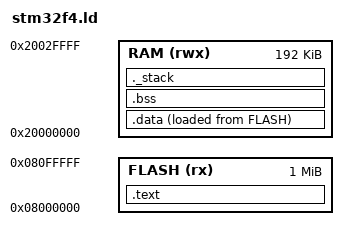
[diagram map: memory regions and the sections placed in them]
ENTRY(Reset_Handler)

MEMORY
{
    FLASH (rx)  : ORIGIN = 0x08000000, LENGTH = 1024K
    RAM   (rwx) : ORIGIN = 0x20000000, LENGTH = 192K
}

SECTIONS
{
    .text :
    {
        KEEP(*(.isr_vector))
        *(.text)
        *(.text*)
        *(.rodata)
        *(.rodata*)
    } > FLASH

    .data :
    {
        _sdata = .;
        *(.data)
        *(.data*)
        _edata = .;
    } > RAM AT > FLASH

    .bss :
    {
        _sbss = .;
        *(.bss)
        *(.bss*)
        *(COMMON)
        _ebss = .;
    } > RAM

    ._stack :
    {
        . = ALIGN(8);
        . = . + 0x400;
        _estack = .;
    } > RAM
}
